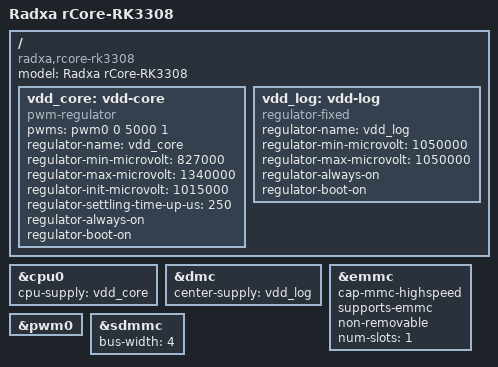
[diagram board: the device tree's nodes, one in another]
// SPDX-License-Identifier: (GPL-2.0+ OR MIT)
/*
 * Copyright (c) 2018 Fuzhou Rockchip Electronics Co., Ltd
 * Copyright (c) 2026 Radxa Computer (Shenzhen) Co., Ltd.
 */

/dts-v1/;
#include "rk3308.dtsi"
#include "rk3308-u-boot.dtsi"

/ {
	model = "Radxa rCore-RK3308";
	compatible = "radxa,rcore-rk3308", "rockchip,rk3308";

	vdd_core: vdd-core {
		compatible = "pwm-regulator";
		pwms = <&pwm0 0 5000 1>;
		regulator-name = "vdd_core";
		regulator-min-microvolt = <827000>;
		regulator-max-microvolt = <1340000>;
		regulator-init-microvolt = <1015000>;
		regulator-settling-time-up-us = <250>;
		regulator-always-on;
		regulator-boot-on;
		status = "okay";
	};

	vdd_log: vdd-log {
		compatible = "regulator-fixed";
		regulator-name = "vdd_log";
		regulator-min-microvolt = <1050000>;
		regulator-max-microvolt = <1050000>;
		regulator-always-on;
		regulator-boot-on;
	};
};

&cpu0 {
	cpu-supply = <&vdd_core>;
};

&dmc {
	center-supply = <&vdd_log>;
	status = "okay";
};

&emmc {
	cap-mmc-highspeed;
	supports-emmc;
	non-removable;
	num-slots = <1>;
	status = "okay";
};

&pwm0 {
	status = "okay";
};

&sdmmc {
	bus-width = <4>;
	status = "okay";
};
